# GD32A72_A74x register map
File version: 1.0
CPU: CM7 r2p1, little endian, MPU, FPU, DSP, 4 interrupt priority bits
Registers are 32-bit, read-write, reset 0x0 unless marked. A register's access mark holds for its fields unless they carry their own. Offsets are from the block's base; [hi:lo] are bit positions; {n}, {i} and the like mark numbered series.

## DBG — Debug
Base 0xE00E1000
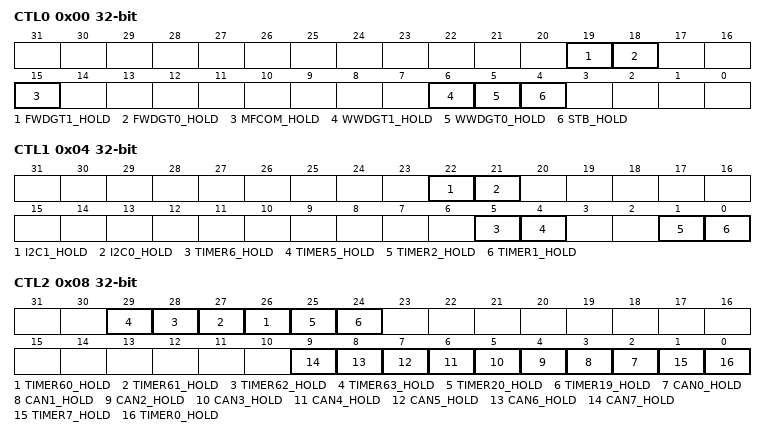
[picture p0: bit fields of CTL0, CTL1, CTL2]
0x00 CTL0 — Control register 0
  [19] FWDGT1_HOLD — fwdgt1 hold bit
  [18] FWDGT0_HOLD — fwdgt0 hold bit
  [15] MFCOM_HOLD — mfcom hold bit
  [6] WWDGT1_HOLD — wwdgt1 hold bit
  [5] WWDGT0_HOLD — wwdgt0 hold bit
  [4] STB_HOLD — standby mode hold bit in register cortex-m7_x (x=0, 1)
0x04 CTL1 — Control register1
  [22] I2C1_HOLD — I2C1 hold bit
  [21] I2C0_HOLD — I2C0 hold bit
  [5] TIMER6_HOLD — TIMER6 hold bit
  [4] TIMER5_HOLD — TIMER5 hold bit
  [1] TIMER2_HOLD — TIMER2 hold bit
  [0] TIMER1_HOLD — TIMER1 hold bit
0x08 CTL2 — Control register2
  [n-34] TIMER{n}_HOLD (n=60..63) — TIMER{n} hold bit
  [25] TIMER20_HOLD — TIMER20 hold bit
  [24] TIMER19_HOLD — TIMER19 hold bit
  [n+2] CAN{n}_HOLD (n=0..7) — CAN{n} hold bit
  [1] TIMER7_HOLD — TIMER7 hold bit
  [0] TIMER0_HOLD — TIMER0 hold bit

## DMAMUX — DMA request multiplexer
Base 0x49000800
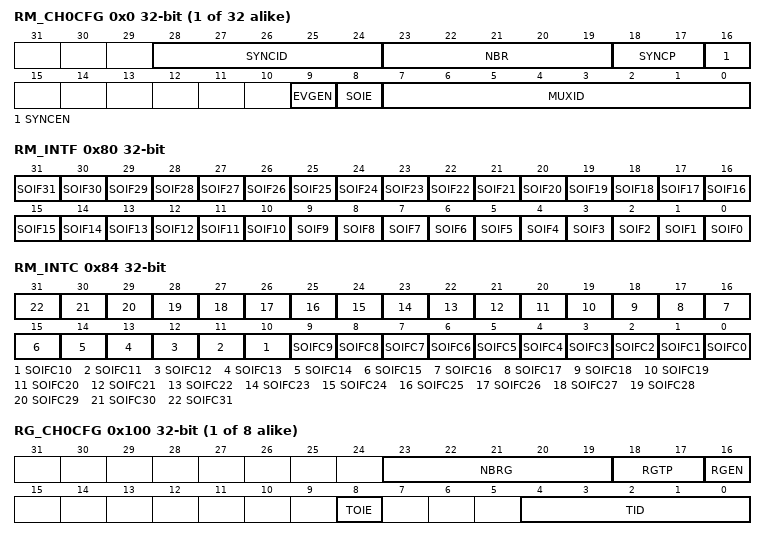
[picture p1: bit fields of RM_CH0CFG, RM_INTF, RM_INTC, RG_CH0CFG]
{0x0+4i} RM_CH{i}CFG (i=0..31) — Request multiplexer channel {i} configuration register
  [28:24] SYNCID — Synchronization input identification
  [23:19] NBR — Number of DMA requests to forward
  [18:17] SYNCP — Synchronization input polarity
  [16] SYNCEN — Synchronization enable
  [9] EVGEN — Event generation enable
  [8] SOIE — Synchronization overrun interrupt enable
  [7:0] MUXID — Multiplexer input identification
0x80 RM_INTF ro — Request multiplexer channel interrupt flag register
  [n] SOIF{n} (n=0..31) — Synchronization overrun event flag of request multiplexer channel {n}
0x84 RM_INTC wo — Request multiplexer channel interrupt flag clear register
  [n] SOIFC{n} (n=0..31) — Clear bit for synchronization overrun event flag of request multiplexer channel {n}
{0x100+4i} RG_CH{i}CFG (i=0..7) — Request generator channel {i} configuration register
  [23:19] NBRG — Number of DMA requests to be generated
  [18:17] RGTP — DMAMUX request generator trigger polarity
  [16] RGEN — DMAMUX request generator channel {i} enable
  [8] TOIE — Trigger overrun interrupt enable
  [4:0] TID — Trigger input identification
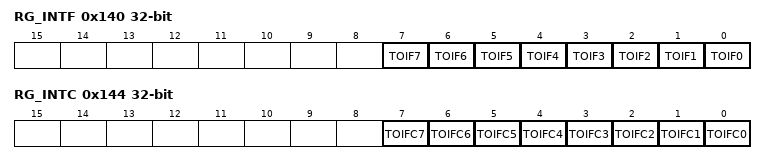
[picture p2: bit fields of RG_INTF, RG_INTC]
0x140 RG_INTF ro — Request generator channel interrupt flag register
  [n] TOIF{n} (n=0..7) — Trigger overrun event flag of request generator channel {n}
0x144 RG_INTC wo — Request generator channel interrupt flag clear register
  [n] TOIFC{n} (n=0..7) — Clear bit for trigger overrun event flag of request generator channel {n}

## EXTI — Interrupt / event controller
Base 0x40010400
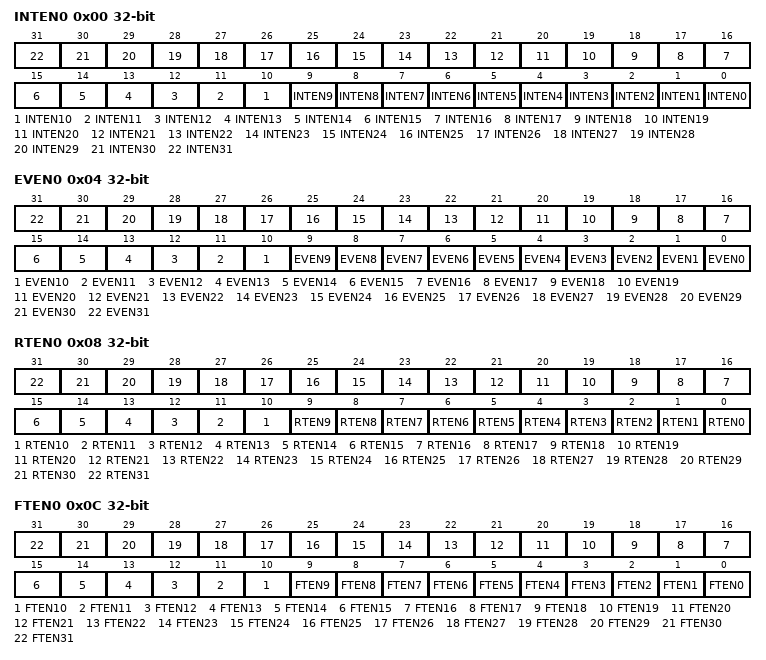
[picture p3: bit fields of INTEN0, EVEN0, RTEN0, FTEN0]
0x00 INTEN0 — Interrupt enable register 0
  [n] INTEN{n} (n=0..31) — interrupt enable bit {n}
0x04 EVEN0 — Event enable register 0
  [n] EVEN{n} (n=0..31) — event enable bit {n}
0x08 RTEN0 — Rising edge trigger enable register 0
  [n] RTEN{n} (n=0..31) — rising edge trigger enable bit {n}
0x0C FTEN0 — Falling edge trigger enable register 0
  [n] FTEN{n} (n=0..31) — falling edge trigger enable bit {n}
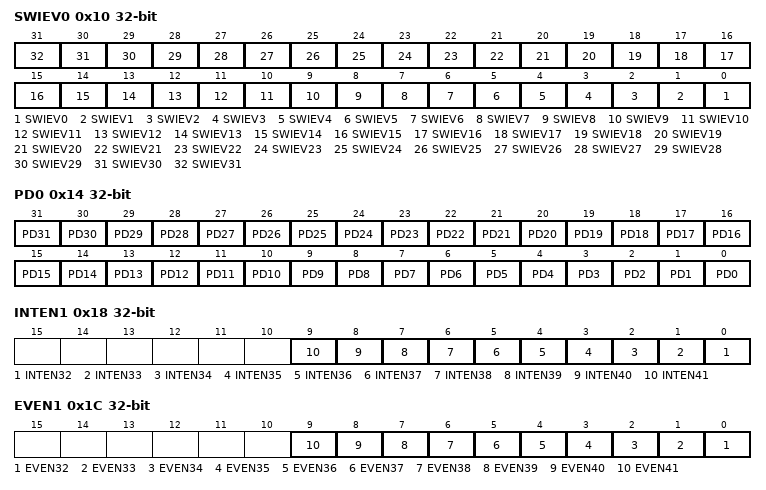
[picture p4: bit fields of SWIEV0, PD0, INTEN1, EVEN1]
0x10 SWIEV0 — Software interrupt event register 0
  [n] SWIEV{n} (n=0..31) — interrupt / event software trigger bit {n}
0x14 PD0 — Pending register 0
  [n] PD{n} (n=10..31) — interrupt pending status bit {n}
  [9] PD9 — Interrupt pending status bit
  [n] PD{n} (n=0..8) — interrupt pending status bit {n}
0x18 INTEN1 — Interrupt enable register 1
  [n-32] INTEN{n} (n=32..41) — Interrupt enable bit
0x1C EVEN1 — Event enable register 1
  [n-32] EVEN{n} (n=32..41) — Event enable bit
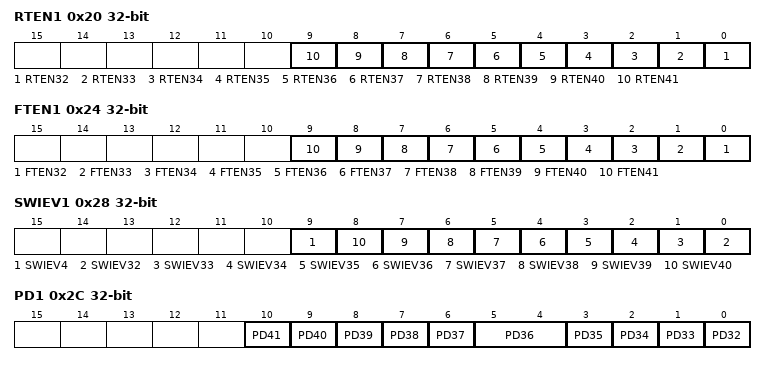
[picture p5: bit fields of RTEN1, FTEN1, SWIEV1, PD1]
0x20 RTEN1 — Rising edge trigger enable register 1
  [n-32] RTEN{n} (n=32..41) — Rising edge trigger enable bit
0x24 FTEN1 — Falling edge trigger enable register 1
  [n-32] FTEN{n} (n=32..41) — Falling edge trigger enable bit
0x28 SWIEV1 — Software interrupt event register 1
  [9] SWIEV4 — Interrupt / event software trigger bit
  [n-32] SWIEV{n} (n=32..40) — Interrupt / event software trigger bit
0x2C PD1 — Pending register 1
  [n-31] PD{n} (n=37..41) — Interrupt pending status bit
  [5:4] PD36 — Interrupt pending status bit
  [n-32] PD{n} (n=32..35) — Interrupt pending status bit
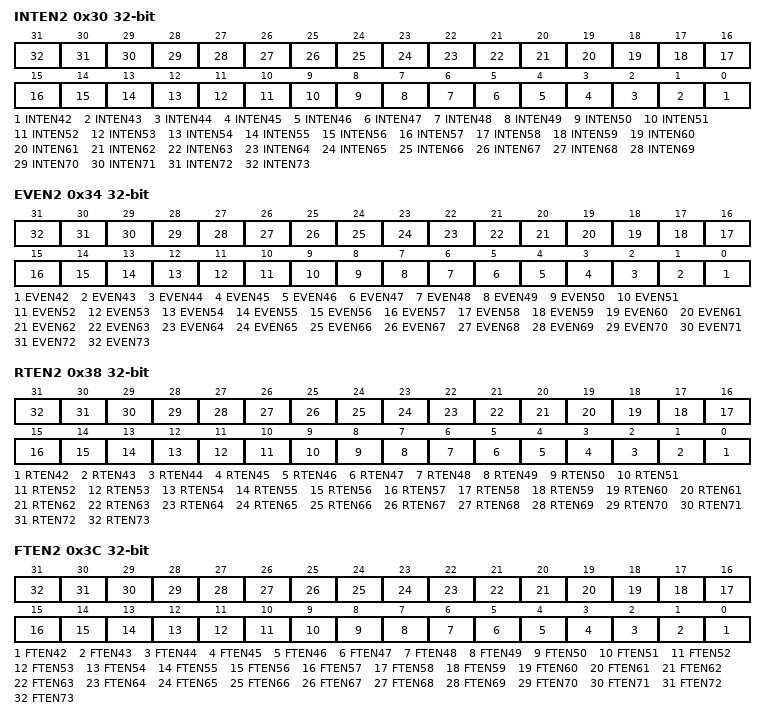
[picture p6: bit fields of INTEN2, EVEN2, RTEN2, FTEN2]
0x30 INTEN2 — Interrupt enable register 2
  [n-42] INTEN{n} (n=42..73) — Interrupt enable bit
0x34 EVEN2 — Event enable register 2
  [n-42] EVEN{n} (n=42..73) — Event enable bit
0x38 RTEN2 — Rising edge trigger enable register 2
  [n-42] RTEN{n} (n=42..73) — Rising edge trigger enable
0x3C FTEN2 — Falling edge trigger enable register 2
  [n-42] FTEN{n} (n=42..73) — Falling edge trigger enable
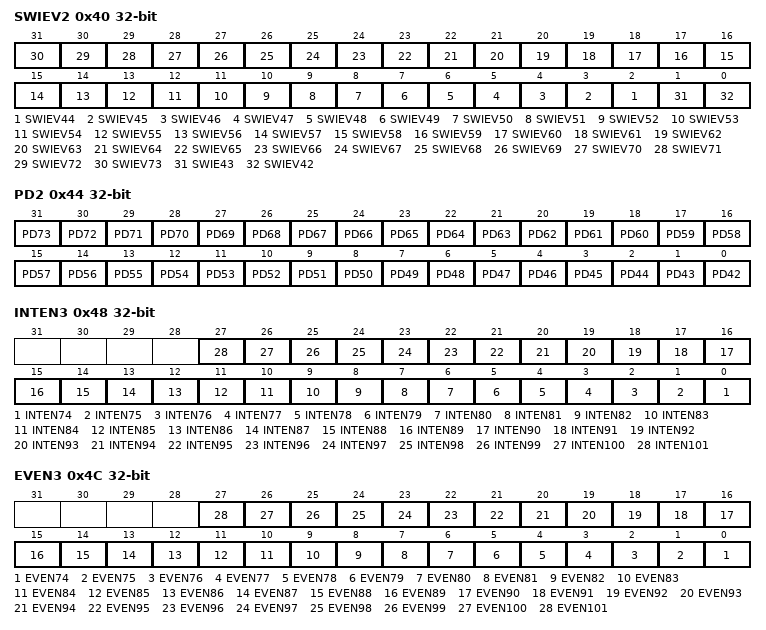
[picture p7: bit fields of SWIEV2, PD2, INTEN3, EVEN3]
0x40 SWIEV2 — Software interrupt event register 2
  [n-42] SWIEV{n} (n=44..73) — Interrupt/Event software trigger
  [1] SWIE43 — Interrupt/Event software trigger
  [0] SWIEV42 — Interrupt/Event software trigger
0x44 PD2 — Pending register 2
  [n-42] PD{n} (n=42..73) — Interrupt pending status
0x48 INTEN3 — Interrupt enable register 3
  [n-74] INTEN{n} (n=74..101) — Interrupt enable bit
0x4C EVEN3 — Event enable register 3
  [n-74] EVEN{n} (n=74..101) — Event enable bit
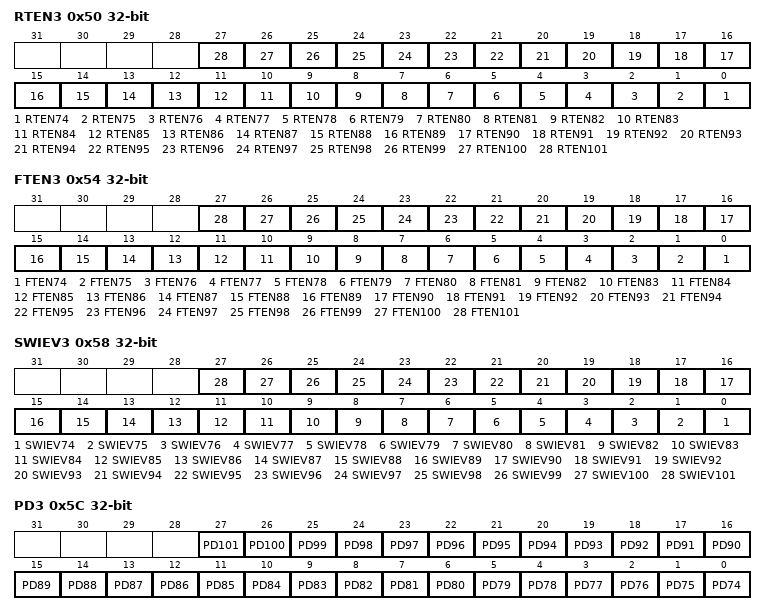
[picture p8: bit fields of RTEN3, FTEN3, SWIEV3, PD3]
0x50 RTEN3 — Rising edge trigger enable register 3
  [n-74] RTEN{n} (n=74..101) — Rising edge trigger enable
0x54 FTEN3 — Falling edge trigger enable register 3
  [n-74] FTEN{n} (n=74..101) — Falling edge trigger enable
0x58 SWIEV3 — Software interrupt event register 3
  [n-74] SWIEV{n} (n=74..101) — Interrupt/Event software trigger
0x5C PD3 — Pending register 3
  [n-74] PD{n} (n=74..101) — Interrupt pending status
